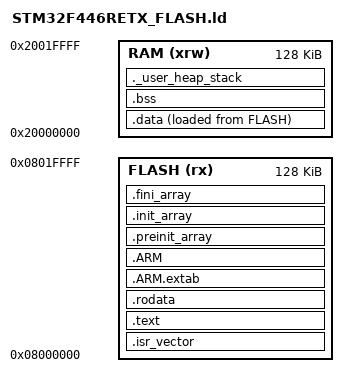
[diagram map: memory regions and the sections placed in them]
/*
******************************************************************************
**
** @file        : LinkerScript.ld
**
**  Device      : STM32F446RETx
**      FLASH   : 512 KBytes total
**      RAM     : 128 KBytes
**
**
**    0x0800 0000 - 0x0801 FFFF  : BOOTLOADER  (128 KB, Sectors 0-4)
**    0x0802 0000 - 0x0805 FFFF  : APPLICATION (256 KB, Sectors 5-6)
**    0x0806 0000 - 0x0806 3FFF  : CFG / DATABASE (16 KB, Sector 7, A/B slot)
**    0x0806 4000 - 0x0807 FFFF  :
**
******************************************************************************
*/

/* Entry Point */
ENTRY(Reset_Handler)

/* Highest address of the user mode stack */
_estack = ORIGIN(RAM) + LENGTH(RAM); /* end of "RAM" Ram type memory */

_Min_Heap_Size = 0x200;  /* required amount of heap */
_Min_Stack_Size = 0x400; /* required amount of stack */


/* Bootloader başlangıç adresi */
BOOT_START = 0x08000000;

APP_START  = 0x08020000;

CFG_START     = 0x08060000;
CFG_SIZE      = 0x00004000;
CFG_SLOT_SIZE = 0x00002000; 

BOOT_FLASH_LEN = APP_START - BOOT_START;

PROVIDE(__boot_start    = BOOT_START);
PROVIDE(__boot_end      = BOOT_START + BOOT_FLASH_LEN);

PROVIDE(__app_start     = APP_START); 
PROVIDE(__cfg_start     = CFG_START);
PROVIDE(__cfg_end       = CFG_START + CFG_SIZE);
PROVIDE(__cfg_slot_size = CFG_SLOT_SIZE);

/* Güvenlik kontrolleri */
ASSERT(BOOT_START < APP_START, "BOOT_START must be below APP_START");
ASSERT(APP_START  < CFG_START, "APP_START must be below CFG_START");
ASSERT(BOOT_FLASH_LEN > 0,     "BOOT flash length must be positive");

/* Memories definition */
MEMORY
{
  RAM   (xrw) : ORIGIN = 0x20000000, LENGTH = 128K

  FLASH (rx)  : ORIGIN = BOOT_START,  LENGTH = BOOT_FLASH_LEN
}

/* Sections */
SECTIONS
{
  /* The startup code into "FLASH" Rom type memory */
  .isr_vector :
  {
    . = ALIGN(4);
    KEEP(*(.isr_vector)) /* Startup code */
    . = ALIGN(4);
  } >FLASH

  /* The program code and other data into "FLASH" Rom type memory */
  .text :
  {
    . = ALIGN(4);
    *(.text)           /* .text sections (code) */
    *(.text*)          /* .text* sections (code) */
    *(.glue_7)         /* glue arm to thumb code */
    *(.glue_7t)        /* glue thumb to arm code */
    *(.eh_frame)

    KEEP (*(.init))
    KEEP (*(.fini))

    . = ALIGN(4);
    _etext = .;        /* define a global symbol at end of code */
  } >FLASH

  /* Constant data into "FLASH" Rom type memory */
  .rodata :
  {
    . = ALIGN(4);
    *(.rodata)         /* .rodata sections (constants, strings, etc.) */
    *(.rodata*)        /* .rodata* sections (constants, strings, etc.) */
    . = ALIGN(4);
  } >FLASH

  .ARM.extab (READONLY) :
  {
    . = ALIGN(4);
    *(.ARM.extab* .gnu.linkonce.armextab.*)
    . = ALIGN(4);
  } >FLASH

  .ARM (READONLY) :
  {
    . = ALIGN(4);
    __exidx_start = .;
    *(.ARM.exidx*)
    __exidx_end = .;
    . = ALIGN(4);
  } >FLASH

  .preinit_array (READONLY) :
  {
    . = ALIGN(4);
    PROVIDE_HIDDEN (__preinit_array_start = .);
    KEEP (*(.preinit_array*))
    PROVIDE_HIDDEN (__preinit_array_end = .);
    . = ALIGN(4);
  } >FLASH

  .init_array (READONLY) :
  {
    . = ALIGN(4);
    PROVIDE_HIDDEN (__init_array_start = .);
    KEEP (*(SORT(.init_array.*)))
    KEEP (*(.init_array*))
    PROVIDE_HIDDEN (__init_array_end = .);
    . = ALIGN(4);
  } >FLASH

  .fini_array (READONLY) :
  {
    . = ALIGN(4);
    PROVIDE_HIDDEN (__fini_array_start = .);
    KEEP (*(SORT(.fini_array.*)))
    KEEP (*(.fini_array*))
    PROVIDE_HIDDEN (__fini_array_end = .);
    . = ALIGN(4);
  } >FLASH

  /* Used by the startup to initialize data */
  _sidata = LOADADDR(.data);

  /* Initialized data sections into "RAM" Ram type memory */
  .data :
  {
    . = ALIGN(4);
    _sdata = .;        /* create a global symbol at data start */
    *(.data)           /* .data sections */
    *(.data*)          /* .data* sections */
    *(.RamFunc)        /* .RamFunc sections */
    *(.RamFunc*)       /* .RamFunc* sections */

    . = ALIGN(4);
    _edata = .;        /* define a global symbol at data end */

  } >RAM AT> FLASH

  /* Uninitialized data section into "RAM" Ram type memory */
  . = ALIGN(4);
  .bss :
  {
    /* This is used by the startup in order to initialize the .bss section */
    _sbss = .;         /* define a global symbol at bss start */
    __bss_start__ = _sbss;
    *(.bss)
    *(.bss*)
    *(COMMON)

    . = ALIGN(4);
    _ebss = .;         /* define a global symbol at bss end */
    __bss_end__ = _ebss;
  } >RAM

  /* User_heap_stack section, used to check that there is enough "RAM" Ram type memory left */
  ._user_heap_stack :
  {
    . = ALIGN(8);
    PROVIDE ( end = . );
    PROVIDE ( _end = . );
    . = . + _Min_Heap_Size;
    . = . + _Min_Stack_Size;
    . = ALIGN(8);
  } >RAM

  /* Remove information from the compiler libraries */
  /DISCARD/ :
  {
    libc.a ( * )
    libm.a ( * )
    libgcc.a ( * )
  }

  .ARM.attributes 0 : { *(.ARM.attributes) }
}
